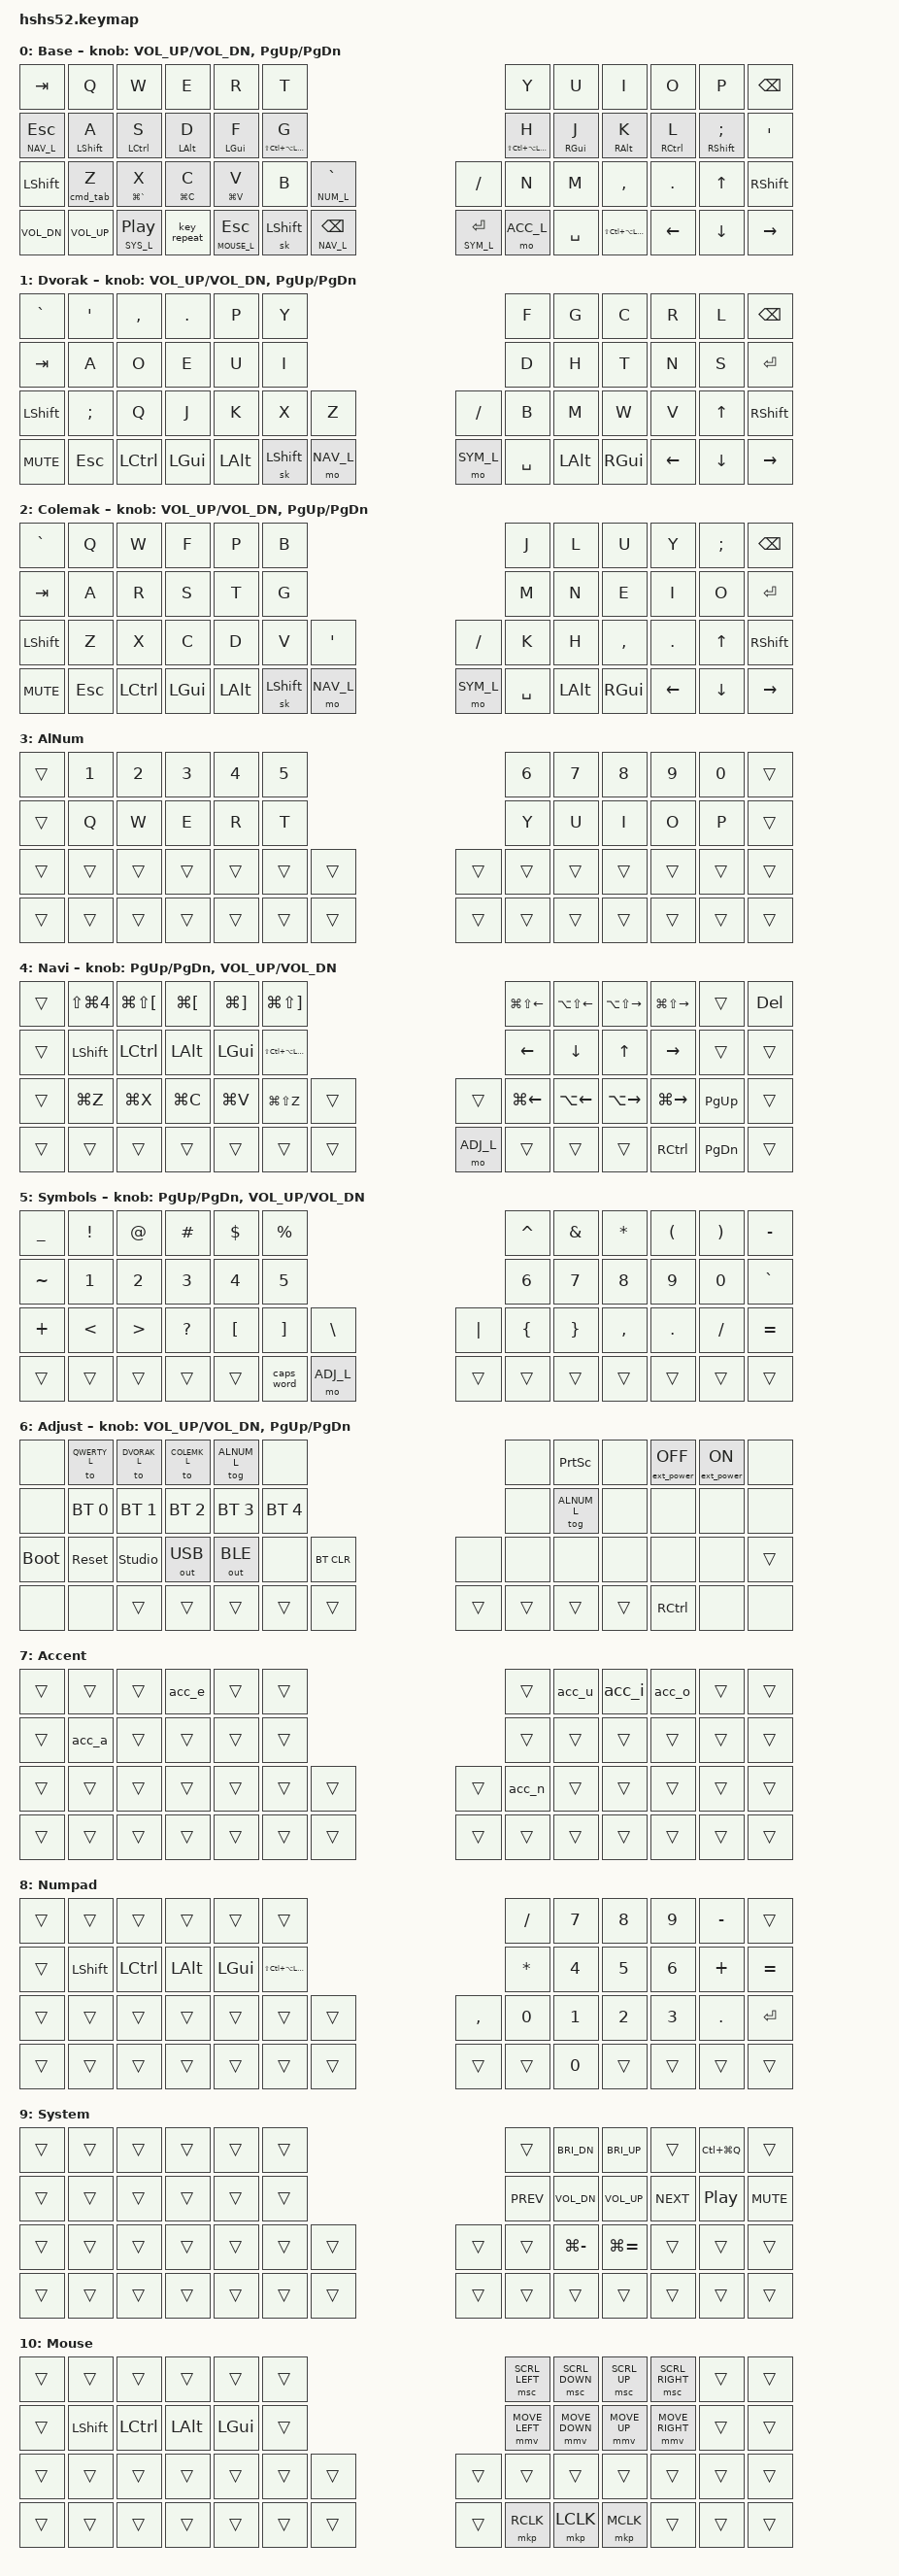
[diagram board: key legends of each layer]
/*
 * Copyright (c) 2021-2022 The ZMK Contributors
 *
 * SPDX-License-Identifier: MIT
 */

#include <behaviors.dtsi>
#include <dt-bindings/zmk/bt.h>
#include <dt-bindings/zmk/ext_power.h>
#include <dt-bindings/zmk/keys.h>
#include <dt-bindings/zmk/outputs.h>

// Mouse keys speed (ZMK defaults: move 600, scroll 10). Tune here if the cursor feels slow or scroll too fast.
#define ZMK_POINTING_DEFAULT_MOVE_VAL 1200
#define ZMK_POINTING_DEFAULT_SCRL_VAL 10
#include <dt-bindings/zmk/pointing.h>

#define QWERTY_L 0
#define DVORAK_L 1
#define COLEMK_L 2
#define ALNUM_L  3
#define NAV_L    4
#define SYM_L    5
#define ADJ_L    6
#define ACC_L    7
#define NUM_L    8
#define SYS_L    9
#define MOUSE_L  10

#define HYPER LS(LC(LA(LGUI)))

#define ACCENT(name, dead, key) \
        name: name { \
                compatible = "zmk,behavior-mod-morph"; \
                #binding-cells = <0>; \
                bindings = <&dead key>, <&dead LS(key)>; \
                mods = <(MOD_LSFT|MOD_RSFT)>; \
        };

// Key positions (see hshs52.dtsi), split by hand for the home row mods.
// Thumbs count for both hands, so mod+space and mod+layer still resolve hold.
#define KEYS_L 0 1 2 3 4 5 12 13 14 15 16 17 24 25 26 27 28 29 30 38 39 40
#define KEYS_R 6 7 8 9 10 11 18 19 20 21 22 23 31 32 33 34 35 36 37 49 50 51
#define THUMBS 41 42 43 44 45 46 47 48


/ {
        behaviors {
                // urob's timeless home row mods, same numbers as the kanata
                // config (nix-config modules/common/kanata.nix, "intento 4"):
                // balanced = kanata's tap-hold-opposite-hand-release. No
                // quick-tap-ms on purpose: it made ⌃C ⌃C come out as "kk".
                hml: home_row_mod_left {
                        compatible = "zmk,behavior-hold-tap";
                        #binding-cells = <2>;
                        flavor = "balanced";
                        tapping-term-ms = <280>;
                        require-prior-idle-ms = <150>;
                        hold-trigger-key-positions = <KEYS_R THUMBS>;
                        hold-trigger-on-release;
                        bindings = <&kp>, <&kp>;
                };

                hmr: home_row_mod_right {
                        compatible = "zmk,behavior-hold-tap";
                        #binding-cells = <2>;
                        flavor = "balanced";
                        tapping-term-ms = <280>;
                        require-prior-idle-ms = <150>;
                        hold-trigger-key-positions = <KEYS_L THUMBS>;
                        hold-trigger-on-release;
                        bindings = <&kp>, <&kp>;
                };

                // Hold c/v/x for ⌘C/⌘V/⌘` (kanata's plain tap-hold 300 300).
                // The hold fires the shortcut once, so macOS can't auto-repeat it.
                hk: hold_shortcut {
                        compatible = "zmk,behavior-hold-tap";
                        #binding-cells = <2>;
                        flavor = "tap-preferred";
                        tapping-term-ms = <300>;
                        bindings = <&tap_once>, <&kp>;
                };

                // Hold z: ⌘ stays down while z is held and Tab is tapped once,
                // so the app switcher stays open; release z to pick the app.
                // Accent layer (hold the right thumb key next to space) + vowel/n.
                // Dead keys use Right Option: terminals like WezTerm treat Left Option as Meta.
                ACCENT(acc_a, acute, A)
                ACCENT(acc_e, acute, E)
                ACCENT(acc_i, acute, I)
                ACCENT(acc_o, acute, O)
                ACCENT(acc_u, acute, U)
                ACCENT(acc_n, tilde, N)

                // Nav, Sym and Mouse thumbs: tap Backspace / Enter / Esc, hold the layer. Balanced so a quick
                // hold+key rolls into the layer; quick-tap lets a double tap hold the key for repeat.
                lt_th: thumb_layer_tap {
                        compatible = "zmk,behavior-hold-tap";
                        #binding-cells = <2>;
                        flavor = "balanced";
                        tapping-term-ms = <200>;
                        quick-tap-ms = <175>;
                        bindings = <&mo>, <&kp>;
                };

                hkz: hold_cmd_tab {
                        compatible = "zmk,behavior-hold-tap";
                        #binding-cells = <2>;
                        flavor = "tap-preferred";
                        tapping-term-ms = <300>;
                        bindings = <&cmd_tab>, <&kp>;
                };
        };

        macros {
                tap_once: tap_once {
                        compatible = "zmk,behavior-macro-one-param";
                        #binding-cells = <1>;
                        bindings = <&macro_param_1to1>, <&macro_tap &kp MACRO_PLACEHOLDER>;
                };

                acute: acute {
                        compatible = "zmk,behavior-macro-one-param";
                        #binding-cells = <1>;
                        bindings = <&macro_tap &kp RA(E)>, <&macro_param_1to1>, <&macro_tap &kp MACRO_PLACEHOLDER>;
                };

                tilde: tilde {
                        compatible = "zmk,behavior-macro-one-param";
                        #binding-cells = <1>;
                        bindings = <&macro_tap &kp RA(N)>, <&macro_param_1to1>, <&macro_tap &kp MACRO_PLACEHOLDER>;
                };

                cmd_tab: cmd_tab {
                        compatible = "zmk,behavior-macro";
                        #binding-cells = <0>;
                        wait-ms = <20>;
                        bindings
                                = <&macro_press &kp LGUI>
                                , <&macro_tap &kp TAB>
                                , <&macro_pause_for_release>
                                , <&macro_release &kp LGUI>
                                ;
                };
        };

        keymap {
                compatible = "zmk,keymap";

                default_layer {
                        display-name = "Base";
/* QWERTY   (' and Enter-on-thumb like linkarzu; a s d f g / ; l k j h held = ⇧ ⌃ ⌥ ⌘ Hyper;  z x c v held = ⌘Tab ⌘` ⌘C ⌘V;  Rep = repeat the last key or shortcut;  Esc held = Nav, like linkarzu)
 * -------------------------------------------------------------------------------------------------------------------------------------
 * | TAB   |   Q   |   W   |   E   |   R   |   T   |-----------------------------------|   Y   |   U   |   I   |   O   |   P   | BKSPC |
 * |ESC/Nav| A/⇧   | S/⌃   | D/⌥   | F/⌘   | G/Hyp |-----------------------------------| H/Hyp | J/⌘   | K/⌥   | L/⌃   | ;/⇧   |   '   |
 * | SHIFT | Z/⌘⇥  | X/⌘`  | C/⌘C  | V/⌘V  |   B   |` ~/Num|-------------------|   /   |   N   |   M   |   ,   |   .   |  Up   | SHIFT |
 * | Vol-  | Vol+  |⏯/Sys  |-------|  Rep  |Esc/Mou|SK SHFT| ⌫/Nav |---|Ent/Sym|Accent | SPACE | Hyper |-------| Left  | Down  | Right |
 */
                        bindings = <
&kp  TAB      &kp  Q        &kp  W        &kp  E        &kp  R        &kp  T                                                                         &kp  Y        &kp  U        &kp  I        &kp  O        &kp  P        &kp  BSPC
&lt NAV_L ESC &hml LSHFT A  &hml LCTRL S  &hml LALT D   &hml LGUI F   &hml HYPER G                                                                   &hmr HYPER H  &hmr RGUI J   &hmr RALT K   &hmr RCTRL L  &hmr RSHFT SEMI &kp  SQT
&kp  LSHFT    &hkz 0 Z      &hk LG(GRAVE) X &hk LG(C) C &hk LG(V) V   &kp  B        &lt NUM_L GRAVE                                    &kp  SLASH    &kp  N        &kp  M        &kp  COMMA    &kp  DOT      &kp  UP       &kp  RSHFT
&kp  C_VOL_DN &kp C_VOL_UP  &lt SYS_L C_PP              &key_repeat   &lt_th MOUSE_L ESC &sk LSHIFT    &lt_th NAV_L BSPC     &lt_th SYM_L ENTER &mo  ACC_L    &kp  SPACE    &kp  HYPER                   &kp  LEFT     &kp  DOWN     &kp  RIGHT
                        >;

                        sensor-bindings = <&inc_dec_kp C_VOL_UP C_VOL_DN &inc_dec_kp PG_UP PG_DN>;
                };

                dvorak_layer {
                        display-name = "Dvorak";
/* DVORAK
 * -------------------------------------------------------------------------------------------------------------------------------------
 * | `     |   '   |   ,   |   .   |   P   |   Y   |-----------------------------------|   F   |   G   |   C   |   R   |   L   | BKSPC |
 * | TAB   |   A   |   O   |   E   |   U   |   I   |-----------------------------------|   D   |   H   |   T   |   N   |   S   | ENTER |
 * | SHIFT |   ;   |   Q   |   J   |   K   |   X   |   Z   |-------------------|   /   |   B   |   M   |   W   |   V   |  Up   | SHIFT |
 * | Mute  |  ESC  | CTRL  |-------|  GUI  |  ALT  |SK SHFT|  Nav  |---|  Sym  | SPACE |  ALT  |  GUI  |-------| Left  | Down  | Right |
 */
                        bindings = <
&kp  GRAVE    &kp  SQT      &kp  COMMA    &kp  DOT      &kp  P        &kp  Y                                                                         &kp  F        &kp  G        &kp  C        &kp  R        &kp  L        &kp  BSPC
&kp  TAB      &kp  A        &kp  O        &kp  E        &kp  U        &kp  I                                                                         &kp  D        &kp  H        &kp  T        &kp  N        &kp  S        &kp  ENTER
&kp  LSHFT    &kp  SEMI     &kp  Q        &kp  J        &kp  K        &kp  X        &kp  Z                                             &kp  SLASH    &kp  B        &kp  M        &kp  W        &kp  V        &kp  UP       &kp  RSHFT
&kp  C_MUTE   &kp  ESC      &kp  LCTRL                  &kp  LGUI     &kp  LALT     &sk  LSHIFT    &mo  NAV_L            &mo  SYM_L    &kp  SPACE    &kp  LALT     &kp  RGUI                   &kp  LEFT     &kp  DOWN     &kp  RIGHT
                        >;

                        sensor-bindings = <&inc_dec_kp C_VOL_UP C_VOL_DN &inc_dec_kp PG_UP PG_DN>;
                };

                colemak_layer {
                        display-name = "Colemak";
/* COLEMAK-DH
 * -------------------------------------------------------------------------------------------------------------------------------------
 * | `     |   Q   |   W   |   F   |   P   |   B   |-----------------------------------|   J   |   L   |   U   |   Y   |   ;   | BKSPC |
 * | TAB   |   A   |   R   |   S   |   T   |   G   |-----------------------------------|   M   |   N   |   E   |   I   |   O   | ENTER |
 * | SHIFT |   Z   |   X   |   C   |   D   |   V   |   '   |-------------------|   /   |   K   |   H   |   ,   |   .   |  Up   | SHIFT |
 * | Mute  |  ESC  | CTRL  |-------|  GUI  |  ALT  |SK SHFT|  Nav  |---|  Sym  | SPACE |  ALT  |  GUI  |-------| Left  | Down  | Right |
 */
                        bindings = <
&kp  GRAVE    &kp  Q        &kp  W        &kp  F        &kp  P        &kp  B                                                                         &kp  J        &kp  L        &kp  U        &kp  Y        &kp  SEMI     &kp  BSPC
&kp  TAB      &kp  A        &kp  R        &kp  S        &kp  T        &kp  G                                                                         &kp  M        &kp  N        &kp  E        &kp  I        &kp  O        &kp  ENTER
&kp  LSHFT    &kp  Z        &kp  X        &kp  C        &kp  D        &kp  V        &kp  SQT                                           &kp  SLASH    &kp  K        &kp  H        &kp  COMMA    &kp  DOT      &kp  UP       &kp  RSHFT
&kp  C_MUTE   &kp  ESC      &kp  LCTRL                  &kp  LGUI     &kp  LALT     &sk  LSHIFT     &mo  NAV_L           &mo  SYM_L    &kp  SPACE    &kp  LALT     &kp  RGUI                   &kp  LEFT     &kp  DOWN     &kp  RIGHT
                        >;

                        sensor-bindings = <&inc_dec_kp C_VOL_UP C_VOL_DN &inc_dec_kp PG_UP PG_DN>;
                };

                alnum_layer {
                        display-name = "AlNum";
/* ALNUM   (toggle from Adjust: numbers on top, the qwerty top row below; shift works)
 * Sits below Nav/Sym/Adjust so those still work, and Adjust can toggle it off.
 * |       |   1   |   2   |   3   |   4   |   5   |-----------------------------------|   6   |   7   |   8   |   9   |   0   |       |
 * |       |   Q   |   W   |   E   |   R   |   T   |-----------------------------------|   Y   |   U   |   I   |   O   |   P   |       |
 */
                        bindings = <
&trans        &kp  N1       &kp  N2       &kp  N3       &kp  N4       &kp  N5                                                                        &kp  N6       &kp  N7       &kp  N8       &kp  N9       &kp  N0       &trans
&trans        &kp  Q        &kp  W        &kp  E        &kp  R        &kp  T                                                                         &kp  Y        &kp  U        &kp  I        &kp  O        &kp  P        &trans
&trans        &trans        &trans        &trans        &trans        &trans        &trans                                             &trans        &trans        &trans        &trans        &trans        &trans        &trans
&trans        &trans        &trans                      &trans        &trans        &trans        &trans                 &trans        &trans        &trans        &trans                      &trans        &trans        &trans
                        >;
                };

                nav_layer {
                        display-name = "Navi";
/* NAV   (kanata's navi: callum mods on the left home row, vim arrows on the right; below them ⌘← ⌥← ⌥→ ⌘→ jump to
 *         line start / word back / word forward / line end, and the same keys above them add ⇧ to select;
 *         Q = CleanShot area capture ⌘⇧4; W E R T = previous tab, back, forward, next tab; Z X C V B = undo cut copy paste redo)
 * -------------------------------------------------------------------------------------------------------------------------------------
 * |       | Shot  | Tab ← | Back  |  Fwd  | Tab → |-----------------------------------|  ⌘⇧←  |  ⌥⇧←  |  ⌥⇧→  |  ⌘⇧→  |       |  DEL  |
 * |       |   ⇧   |   ⌃   |   ⌥   |   ⌘   | Hyper |-----------------------------------| Left  | Down  |  Up   | Right |       |       |
 * |       | Undo  |  Cut  | Copy  | Paste | Redo  |       |-------------------|       |  ⌘←   |  ⌥←   |  ⌥→   |  ⌘→   | PG UP |       |
 * |       |       |       |-------|       |       |       |       |---| ADJ_L |       |       |       |-------| CTRL  | PG DN |       |
 */
                        bindings = <
&trans        &kp LS(LG(N4)) &kp LG(LS(LBKT)) &kp LG(LBKT) &kp LG(RBKT)  &kp LG(LS(RBKT))                                                                        &kp LG(LS(LEFT)) &kp LA(LS(LEFT)) &kp LA(LS(RIGHT)) &kp LG(LS(RIGHT)) &trans &kp  DEL
&trans        &kp  LSHFT    &kp  LCTRL    &kp  LALT     &kp  LGUI     &kp  HYPER                                                                     &kp  LEFT     &kp  DOWN     &kp  UP       &kp  RIGHT    &trans        &trans
&trans        &kp LG(Z)     &kp LG(X)     &kp LG(C)     &kp LG(V)     &kp LG(LS(Z)) &trans                                             &trans        &kp LG(LEFT)  &kp LA(LEFT)  &kp LA(RIGHT) &kp LG(RIGHT) &kp  PG_UP    &trans
&trans        &trans        &trans                      &trans        &trans        &trans        &trans                 &mo ADJ_L     &trans        &trans        &trans                     &kp  RCTRL    &kp  PG_DN    &trans
                        >;

                        sensor-bindings = <&inc_dec_kp PG_UP PG_DN &inc_dec_kp C_VOL_UP C_VOL_DN>;
                };

                sym_layer {
                        display-name = "Symbols";
/* SYM   (linkarzu's Symb layer; \ | on the inner keys since he has no room for them here)
 * -------------------------------------------------------------------------------------------------------------------------------------
 * |   _   |   !   |   @   |   #   |   $   |   %   |-----------------------------------|   ^   |   &   |   *   |   (   |   )   |   -   |
 * |   ~   |   1   |   2   |   3   |   4   |   5   |-----------------------------------|   6   |   7   |   8   |   9   |   0   |   `   |
 * |   +   |   <   |   >   |   ?   |   [   |   ]   |   \   |-------------------|   |   |   {   |   }   |   ,   |   .   |   /   |   =   |
 * |       |       |       |-------|       |       | CAPS  |  ADJ_L |---|      |       |       |       |-------|       |       |       |
 */
                        bindings = <
&kp  UNDER    &kp  EXCL     &kp  AT       &kp  HASH     &kp  DOLLAR   &kp  PERCENT                                                                   &kp  CARET    &kp  AMPS     &kp  ASTRK    &kp  LPAR     &kp  RPAR     &kp  MINUS
&kp  TILDE    &kp  N1       &kp  N2       &kp  N3       &kp  N4       &kp  N5                                                                        &kp  N6       &kp  N7       &kp  N8       &kp  N9       &kp  N0       &kp  GRAVE
&kp  PLUS     &kp  LT       &kp  GT       &kp  QMARK    &kp  LBKT     &kp  RBKT     &kp  BSLH                                          &kp  PIPE     &kp  LBRC     &kp  RBRC     &kp  COMMA    &kp  DOT      &kp  FSLH     &kp  EQUAL
&trans        &trans        &trans                      &trans        &trans        &caps_word    &mo  ADJ_L               &trans      &trans        &trans        &trans                      &trans        &trans        &trans
                        >;

                        sensor-bindings = <&inc_dec_kp PG_UP PG_DN &inc_dec_kp C_VOL_UP C_VOL_DN>;
                };


                adj_layer {
                        display-name = "Adjust";
/* ADJUST
 * -------------------------------------------------------------------------------------------------------------------------------------
 * |       | QWERTY| DVORAK| COLEMK| AlNum |       |-----------------------------------|       |Prt Scr|       | EP_OFF| EP_ON |       |
 * |       | BT 0  | BT 1  | BT 2  | BT 3  | BT 4  |-----------------------------------|       | AlNum |       |       |       |       |
 * | BOOTL | RESET | STUDIO|OUT_USB|OUT_BLE|       |BT CLR |-------------------|       |       |       |       |       |       | SHIFT |
 * ----------------|       |-------|       |       |       |       |---|       |       |       |       |-------| CTRL  |----------------
 */
                        bindings = <
&none         &to  QWERTY_L &to  DVORAK_L &to  COLEMK_L &tog ALNUM_L        &none                                                                             &none             &kp PRINTSCREEN    &none         &ext_power EP_OFF  &ext_power EP_ON &none
&none         &bt  BT_SEL 0 &bt  BT_SEL 1 &bt  BT_SEL 2 &bt  BT_SEL 3 &bt  BT_SEL 4                                                                     &none             &tog ALNUM_L              &none            &none           &none            &none
&bootloader   &sys_reset        &studio_unlock 	&out OUT_USB  &out OUT_BLE  &none         &bt BT_CLR                                         &none            &none             &none              &none            &none           &none            &trans
&none         &none         &trans                      &trans        &trans        &trans        &trans                 &trans        &trans           &trans            &trans                              &kp  RCTRL      &none            &none
                        >;

                        sensor-bindings = <&inc_dec_kp C_VOL_UP C_VOL_DN &inc_dec_kp PG_UP PG_DN>;
                };

                accent_layer {
                        display-name = "Accent";
/* ACCENT   (hold the thumb key left of space; add shift for capitals)
 * |       |       |       |   é   |       |       |-----------------------------------|       |   ú   |   í   |   ó   |       |       |
 * |       |   á   |       |       |       |       |-----------------------------------|       |       |       |       |       |       |
 * |       |       |       |       |       |       |       |-------------------|       |   ñ   |       |       |       |       |       |
 */
                        bindings = <
&trans        &trans        &trans        &acc_e        &trans        &trans                                                                         &trans        &acc_u        &acc_i        &acc_o        &trans        &trans
&trans        &acc_a        &trans        &trans        &trans        &trans                                                                         &trans        &trans        &trans        &trans        &trans        &trans
&trans        &trans        &trans        &trans        &trans        &trans        &trans                                             &trans        &acc_n        &trans        &trans        &trans        &trans        &trans
&trans        &trans        &trans                      &trans        &trans        &trans        &trans                 &trans        &trans        &trans        &trans                      &trans        &trans        &trans
                        >;
                };

                num_layer {
                        display-name = "Numpad";
/* NUMPAD   (hold the ` key right of B: numpad on the right hand, callum mods on the left; , and . both for decimals)
 * -------------------------------------------------------------------------------------------------------------------------------------
 * |       |       |       |       |       |       |-----------------------------------|   /   |   7   |   8   |   9   |   -   |       |
 * |       |   ⇧   |   ⌃   |   ⌥   |   ⌘   | Hyper |-----------------------------------|   *   |   4   |   5   |   6   |   +   |   =   |
 * |       |       |       |       |       |       |       |-------------------|   ,   |   0   |   1   |   2   |   3   |   .   | ENTER |
 * |       |       |       |-------|       |       |       |       |---|       |       |   0   |       |-------|       |       |       |
 */
                        bindings = <
&trans        &trans        &trans        &trans        &trans        &trans                                                                         &kp  FSLH     &kp  N7       &kp  N8       &kp  N9       &kp  MINUS    &trans
&trans        &kp  LSHFT    &kp  LCTRL    &kp  LALT     &kp  LGUI     &kp  HYPER                                                                     &kp  ASTRK    &kp  N4       &kp  N5       &kp  N6       &kp  PLUS     &kp  EQUAL
&trans        &trans        &trans        &trans        &trans        &trans        &trans                                             &kp  COMMA    &kp  N0       &kp  N1       &kp  N2       &kp  N3       &kp  DOT      &kp  ENTER
&trans        &trans        &trans                      &trans        &trans        &trans        &trans                 &trans        &trans        &kp  N0       &trans                      &trans        &trans        &trans
                        >;
                };

                sys_layer {
                        display-name = "System";
/* SYSTEM   (hold the Play key, third from the bottom-left; from linkarzu's Systm layer, laid out like the Nav arrows:
 *           ← → = previous/next track, ↓ ↑ = less/more, brightness above volume, zoom below)
 * -------------------------------------------------------------------------------------------------------------------------------------
 * |       |       |       |       |       |       |-----------------------------------|       | Bri-  | Bri+  |       | Lock  |       |
 * |       |       |       |       |       |       |-----------------------------------| Prev  | Vol-  | Vol+  | Next  | Play  | Mute  |
 * |       |       |       |       |       |       |       |-------------------|       |       |Zoom - |Zoom + |       |       |       |
 */
                        bindings = <
&trans        &trans        &trans        &trans        &trans        &trans                                                                         &trans        &kp  C_BRI_DN &kp  C_BRI_UP &trans        &kp LC(LG(Q)) &trans
&trans        &trans        &trans        &trans        &trans        &trans                                                                         &kp  C_PREV   &kp  C_VOL_DN &kp  C_VOL_UP &kp  C_NEXT   &kp  C_PP     &kp  C_MUTE
&trans        &trans        &trans        &trans        &trans        &trans        &trans                                             &trans        &trans        &kp LG(MINUS) &kp LG(EQUAL) &trans        &trans        &trans
&trans        &trans        &trans                      &trans        &trans        &trans        &trans                 &trans        &trans        &trans        &trans                      &trans        &trans        &trans
                        >;
                };

                mouse_layer {
                        display-name = "Mouse";
/* MOUSE   (hold the left thumb key left of SK SHFT, tap = Esc: cursor on the Nav arrows, scroll above them,
 *          clicks on the right thumbs, callum mods on the left for ⌘click / ⇧click)
 * -------------------------------------------------------------------------------------------------------------------------------------
 * |       |       |       |       |       |       |-----------------------------------| Scr ← | Scr ↓ | Scr ↑ | Scr → |       |       |
 * |       |   ⇧   |   ⌃   |   ⌥   |   ⌘   |       |-----------------------------------|   ←   |   ↓   |   ↑   |   →   |       |       |
 * |       |       |       |       |       |       |       |-------------------|       |       |       |       |       |       |       |
 * |       |       |       |-------|       |       |       |       |---|       |R click|L click|M click|-------|       |       |       |
 */
                        bindings = <
&trans        &trans        &trans        &trans        &trans        &trans                                                                         &msc SCRL_LEFT &msc SCRL_DOWN &msc SCRL_UP &msc SCRL_RIGHT &trans      &trans
&trans        &kp  LSHFT    &kp  LCTRL    &kp  LALT     &kp  LGUI     &trans                                                                         &mmv MOVE_LEFT &mmv MOVE_DOWN &mmv MOVE_UP &mmv MOVE_RIGHT &trans      &trans
&trans        &trans        &trans        &trans        &trans        &trans        &trans                                             &trans        &trans        &trans        &trans        &trans        &trans        &trans
&trans        &trans        &trans                      &trans        &trans        &trans        &trans                 &trans        &mkp RCLK     &mkp LCLK     &mkp MCLK                   &trans        &trans        &trans
                        >;
                };

                extra1 {
                        status = "reserved";
                };

                extra2 {
                        status = "reserved";
                };

                extra3 {
                        status = "reserved";
                };
        };
};
